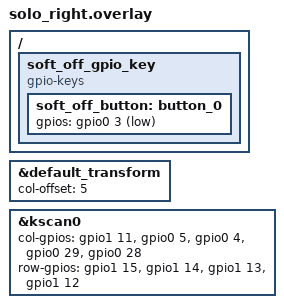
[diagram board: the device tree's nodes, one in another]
#include "solo.dtsi"

&default_transform {
    col-offset = <5>;
};

&kscan0 {
    col-gpios
    = <&gpio1 11 GPIO_ACTIVE_HIGH>
    , <&gpio0 5 GPIO_ACTIVE_HIGH>
    , <&gpio0 4 GPIO_ACTIVE_HIGH>
    , <&gpio0 29 GPIO_ACTIVE_HIGH>
    , <&gpio0 28 GPIO_ACTIVE_HIGH>
    ;

    row-gpios
    = <&gpio1 15 (GPIO_ACTIVE_HIGH | GPIO_PULL_DOWN)>
    , <&gpio1 14 (GPIO_ACTIVE_HIGH | GPIO_PULL_DOWN)>
    , <&gpio1 13 (GPIO_ACTIVE_HIGH | GPIO_PULL_DOWN)>
    , <&gpio1 12 (GPIO_ACTIVE_HIGH | GPIO_PULL_DOWN)>
    ;
 };

/ {
    soft_off_gpio_key {
        compatible = "gpio-keys";
        soft_off_button: button_0 {
            gpios = <&gpio0 3 (GPIO_ACTIVE_LOW | GPIO_PULL_UP)>;
        };
    };
};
